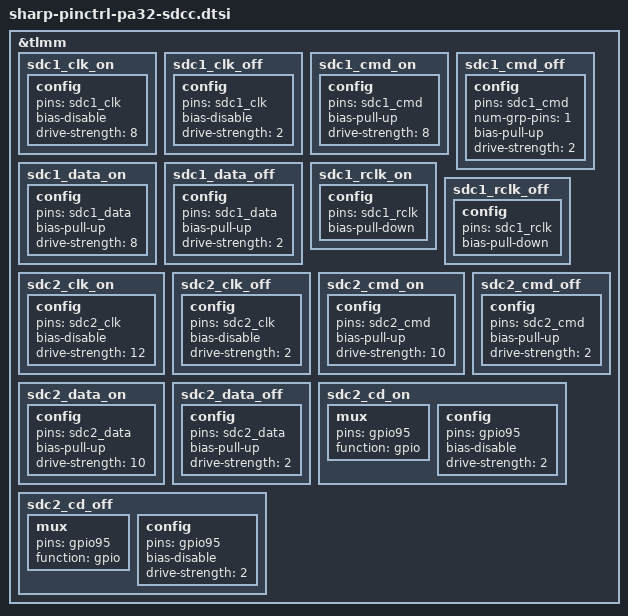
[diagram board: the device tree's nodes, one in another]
/* Copyright (c) 2015, The Linux Foundation. All rights reserved.
 *
 * This program is free software; you can redistribute it and/or modify
 * it under the terms of the GNU General Public License version 2 and
 * only version 2 as published by the Free Software Foundation.
 *
 * This program is distributed in the hope that it will be useful,
 * but WITHOUT ANY WARRANTY; without even the implied warranty of
 * MERCHANTABILITY or FITNESS FOR A PARTICULAR PURPOSE.  See the
 * GNU General Public License for more details.
 */

&tlmm {
	sdc1_clk_on: sdc1_clk_on {
		config {
			pins = "sdc1_clk";
			bias-disable;		/* NO pull */
			drive-strength = <8>;	/* 8 MA */
		};
	};

	sdc1_clk_off: sdc1_clk_off {
		config {
			pins = "sdc1_clk";
			bias-disable;		/* NO pull */
			drive-strength = <2>;	/* 2 MA */
		};
	};

	sdc1_cmd_on: sdc1_cmd_on {
		config {
			pins = "sdc1_cmd";
			bias-pull-up;		/* pull up */
			drive-strength = <8>;	/* 8 MA */
		};
	};

	sdc1_cmd_off: sdc1_cmd_off {
		config {
			pins = "sdc1_cmd";
			num-grp-pins = <1>;
			bias-pull-up;		/* pull up */
			drive-strength = <2>;	/* 2 MA */
		};
	};

	sdc1_data_on: sdc1_data_on {
		config {
			pins = "sdc1_data";
			bias-pull-up;		/* pull up */
			drive-strength = <8>;	/* 8 MA */
		};
	};

	sdc1_data_off: sdc1_data_off {
		config {
			pins = "sdc1_data";
			bias-pull-up;		/* pull up */
			drive-strength = <2>;	/* 2 MA */
		};
	};

	sdc1_rclk_on: sdc1_rclk_on {
		config {
			pins = "sdc1_rclk";
			bias-pull-down;		/* pull down */
		};
	};

	sdc1_rclk_off: sdc1_rclk_off {
		config {
			pins = "sdc1_rclk";
			bias-pull-down;		/* pull down */
		};
	};

	sdc2_clk_on: sdc2_clk_on {
		config {
			pins = "sdc2_clk";
			bias-disable;		/* NO pull */
			drive-strength = <12>;	/* 12 MA */
		};
	};

	sdc2_clk_off: sdc2_clk_off {
		config {
			pins = "sdc2_clk";
			bias-disable;		/* NO pull */
			drive-strength = <2>;	/* 2 MA */
		};
	};

	sdc2_cmd_on: sdc2_cmd_on {
		config {
			pins = "sdc2_cmd";
			bias-pull-up;		/* pull up */
			drive-strength = <10>;	/* 10 MA */
		};
	};

	sdc2_cmd_off: sdc2_cmd_off {
		config {
			pins = "sdc2_cmd";
			bias-pull-up;		/* pull up */
			drive-strength = <2>;	/* 2 MA */
		};
	};

	sdc2_data_on: sdc2_data_on {
		config {
			pins = "sdc2_data";
			bias-pull-up;		/* pull up */
			drive-strength = <10>;	/* 10 MA */
		};
	};

	sdc2_data_off: sdc2_data_off {
		config {
			pins = "sdc2_data";
			bias-pull-up;		/* pull up */
			drive-strength = <2>;	/* 2 MA */
		};
	};

	sdc2_cd_on: sdc2_cd_on {
		mux {
			pins = "gpio95";
			function = "gpio";
		};

		config {
			pins = "gpio95";
			/delete-property/ bias-pull-up;		/* pull up */
			bias-disable;		/* non pull */
			drive-strength = <2>;	/* 2 MA */
		};
	};

	sdc2_cd_off: sdc2_cd_off {
		mux {
			pins = "gpio95";
			function = "gpio";
		};

		config {
			pins = "gpio95";
			/delete-property/ bias-pull-up;		/* pull up */
			bias-disable;		/* non pull */
			drive-strength = <2>;	/* 2 MA */
		};
	};
};
